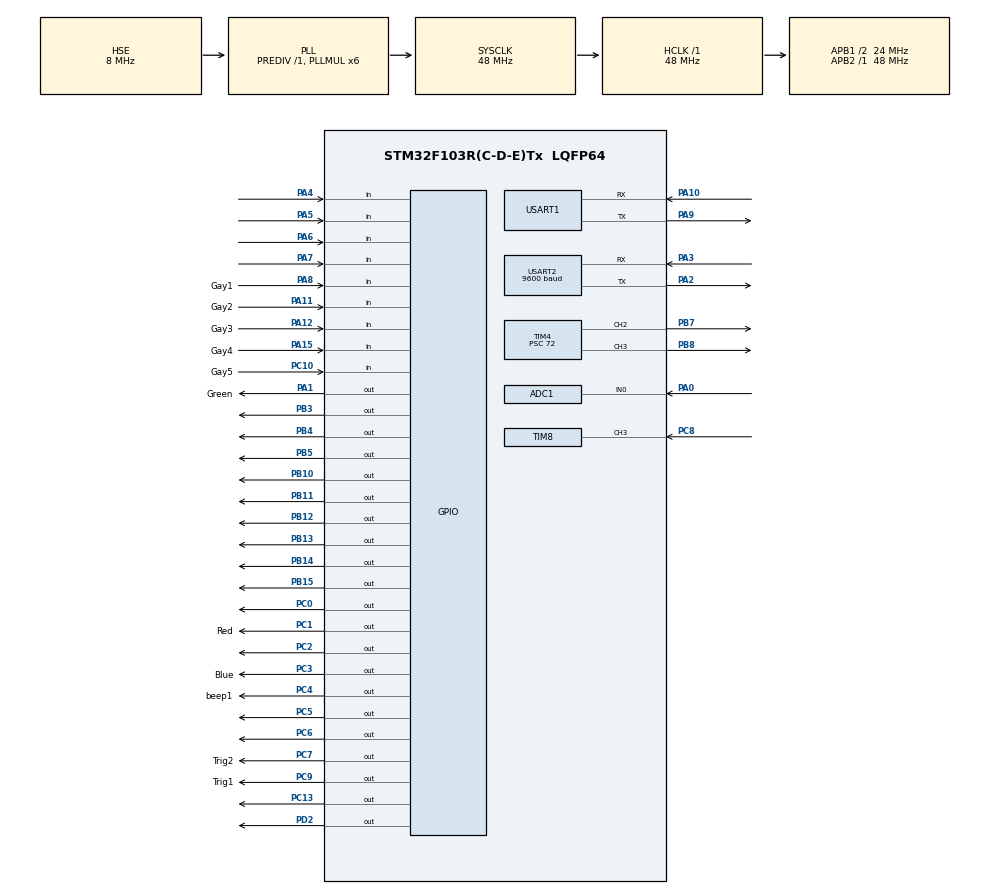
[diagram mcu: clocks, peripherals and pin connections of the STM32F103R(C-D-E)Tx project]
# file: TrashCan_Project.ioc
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ADC1.Channel-4\#ChannelRegularConversion=ADC_CHANNEL_0
ADC1.ContinuousConvMode=DISABLE
ADC1.EnableRegularConversion=ENABLE
ADC1.NbrOfConversion=1
ADC1.NbrOfConversionFlag=1
ADC1.Rank-4\#ChannelRegularConversion=1
ADC1.SamplingTime-4\#ChannelRegularConversion=ADC_SAMPLETIME_1CYCLE_5
ADC1.master=1
Dma.ADC1.0.Direction=DMA_PERIPH_TO_MEMORY
Dma.ADC1.0.Instance=DMA1_Channel1
Dma.ADC1.0.MemDataAlignment=DMA_MDATAALIGN_HALFWORD
Dma.ADC1.0.MemInc=DMA_MINC_ENABLE
Dma.ADC1.0.Mode=DMA_NORMAL
Dma.ADC1.0.PeriphDataAlignment=DMA_PDATAALIGN_HALFWORD
Dma.ADC1.0.PeriphInc=DMA_PINC_DISABLE
Dma.ADC1.0.Priority=DMA_PRIORITY_LOW
Dma.Request0=ADC1
Dma.Request1=USART2_RX
Dma.Request2=USART2_TX
Dma.USART2_RX.1.Direction=DMA_PERIPH_TO_MEMORY
Dma.USART2_RX.1.Instance=DMA1_Channel6
Dma.USART2_RX.1.MemDataAlignment=DMA_MDATAALIGN_BYTE
Dma.USART2_RX.1.MemInc=DMA_MINC_ENABLE
Dma.USART2_RX.1.Mode=DMA_NORMAL
Dma.USART2_RX.1.PeriphDataAlignment=DMA_PDATAALIGN_BYTE
Dma.USART2_RX.1.PeriphInc=DMA_PINC_DISABLE
Dma.USART2_RX.1.Priority=DMA_PRIORITY_LOW
Dma.USART2_TX.2.Direction=DMA_MEMORY_TO_PERIPH
Dma.USART2_TX.2.Instance=DMA1_Channel7
Dma.USART2_TX.2.MemDataAlignment=DMA_MDATAALIGN_BYTE
Dma.USART2_TX.2.MemInc=DMA_MINC_ENABLE
Dma.USART2_TX.2.Mode=DMA_NORMAL
Dma.USART2_TX.2.PeriphDataAlignment=DMA_PDATAALIGN_BYTE
Dma.USART2_TX.2.PeriphInc=DMA_PINC_DISABLE
Dma.USART2_TX.2.Priority=DMA_PRIORITY_LOW
Mcu.Family=STM32F1
Mcu.Name=STM32F103R(C-D-E)Tx
Mcu.Package=LQFP64
NVIC.DMA1_Channel1_IRQn=true\:0\:0\:false\:false\:true\:false\:true\:true
NVIC.DMA1_Channel6_IRQn=true\:0\:0\:false\:false\:true\:false\:true\:true
NVIC.DMA1_Channel7_IRQn=true\:0\:0\:false\:false\:true\:false\:true\:true
NVIC.PriorityGroup=NVIC_PRIORITYGROUP_4
NVIC.TIM6_IRQn=true\:0\:0\:false\:false\:true\:true\:true\:true
NVIC.TIM8_CC_IRQn=true\:0\:0\:false\:false\:true\:true\:true\:true
NVIC.USART2_IRQn=true\:0\:0\:false\:false\:true\:true\:true\:true
PA0-WKUP.Signal=ADCx_IN0
PA1.GPIO_Label=Green
PA1.Signal=GPIO_Output
PA10.Mode=Asynchronous
PA10.Signal=USART1_RX
PA11.GPIO_Label=Gay2
PA11.Signal=GPIO_Input
PA12.GPIO_Label=Gay3
PA12.Signal=GPIO_Input
PA13.Mode=Serial_Wire
PA13.Signal=SYS_JTMS-SWDIO
PA14.Mode=Serial_Wire
PA14.Signal=SYS_JTCK-SWCLK
PA15.GPIO_Label=Gay4
PA15.Signal=GPIO_Input
PA2.Mode=Asynchronous
PA2.Signal=USART2_TX
PA3.Mode=Asynchronous
PA3.Signal=USART2_RX
PA4.Signal=GPIO_Input
PA5.Signal=GPIO_Input
PA6.Signal=GPIO_Input
PA7.Signal=GPIO_Input
PA8.GPIO_Label=Gay1
PA8.Signal=GPIO_Input
PA9.Mode=Asynchronous
PA9.Signal=USART1_TX
PB10.GPIO_ModeDefaultOutputPP=GPIO_MODE_OUTPUT_OD
PB10.GPIO_PuPd=GPIO_PULLUP
PB10.GPIO_Speed=GPIO_SPEED_FREQ_HIGH
PB10.Signal=GPIO_Output
PB11.GPIO_ModeDefaultOutputPP=GPIO_MODE_OUTPUT_OD
PB11.GPIO_PuPd=GPIO_PULLUP
PB11.GPIO_Speed=GPIO_SPEED_FREQ_HIGH
PB11.Signal=GPIO_Output
PB12.GPIO_ModeDefaultOutputPP=GPIO_MODE_OUTPUT_OD
PB12.GPIO_PuPd=GPIO_NOPULL
PB12.GPIO_Speed=GPIO_SPEED_FREQ_HIGH
PB12.PinState=GPIO_PIN_RESET
PB12.Signal=GPIO_Output
PB13.GPIO_ModeDefaultOutputPP=GPIO_MODE_OUTPUT_PP
PB13.GPIO_PuPd=GPIO_NOPULL
PB13.GPIO_Speed=GPIO_SPEED_FREQ_MEDIUM
PB13.PinState=GPIO_PIN_SET
PB13.Signal=GPIO_Output
PB14.GPIO_ModeDefaultOutputPP=GPIO_MODE_OUTPUT_OD
PB14.GPIO_PuPd=GPIO_PULLUP
PB14.GPIO_Speed=GPIO_SPEED_FREQ_HIGH
PB14.PinState=GPIO_PIN_SET
PB14.Signal=GPIO_Output
PB15.GPIO_ModeDefaultOutputPP=GPIO_MODE_OUTPUT_OD
PB15.GPIO_PuPd=GPIO_PULLUP
PB15.GPIO_Speed=GPIO_SPEED_FREQ_HIGH
PB15.PinState=GPIO_PIN_RESET
PB15.Signal=GPIO_Output
PB3.Signal=GPIO_Output
PB4.Signal=GPIO_Output
PB5.Signal=GPIO_Output
PB7.Signal=S_TIM4_CH2
PB8.Signal=S_TIM4_CH3
PC0.GPIO_ModeDefaultOutputPP=GPIO_MODE_OUTPUT_OD
PC0.GPIO_PuPd=GPIO_PULLUP
PC0.GPIO_Speed=GPIO_SPEED_FREQ_HIGH
PC0.PinState=GPIO_PIN_RESET
PC0.Signal=GPIO_Output
PC1.GPIO_Label=Red
PC1.Signal=GPIO_Output
PC10.GPIO_Label=Gay5
PC10.Signal=GPIO_Input
PC13-TAMPER-RTC.GPIO_ModeDefaultOutputPP=GPIO_MODE_OUTPUT_OD
PC13-TAMPER-RTC.GPIO_PuPd=GPIO_PULLUP
PC13-TAMPER-RTC.GPIO_Speed=GPIO_SPEED_FREQ_HIGH
PC13-TAMPER-RTC.PinState=GPIO_PIN_RESET
PC13-TAMPER-RTC.Signal=GPIO_Output
PC2.Signal=GPIO_Output
PC3.GPIO_Label=Blue
PC3.Signal=GPIO_Output
PC4.GPIO_Label=beep1
PC4.GPIO_ModeDefaultOutputPP=GPIO_MODE_OUTPUT_PP
PC4.GPIO_PuPd=GPIO_PULLDOWN
PC4.PinState=GPIO_PIN_SET
PC4.Signal=GPIO_Output
PC5.GPIO_ModeDefaultOutputPP=GPIO_MODE_OUTPUT_OD
PC5.GPIO_PuPd=GPIO_PULLUP
PC5.GPIO_Speed=GPIO_SPEED_FREQ_HIGH
PC5.Signal=GPIO_Output
PC6.GPIO_ModeDefaultOutputPP=GPIO_MODE_OUTPUT_OD
PC6.GPIO_PuPd=GPIO_PULLUP
PC6.GPIO_Speed=GPIO_SPEED_FREQ_HIGH
PC6.Signal=GPIO_Output
PC7.GPIO_Label=Trig2
PC7.Signal=GPIO_Output
PC8.Signal=S_TIM8_CH3
PC9.GPIO_Label=Trig1
PC9.Signal=GPIO_Output
PD0-OSC_IN.Mode=HSE-External-Oscillator
PD0-OSC_IN.Signal=RCC_OSC_IN
PD1-OSC_OUT.Mode=HSE-External-Oscillator
PD1-OSC_OUT.Signal=RCC_OSC_OUT
PD2.Signal=GPIO_Output
ProjectManager.HeapSize=0x200
ProjectManager.StackSize=0x400
ProjectManager.TargetToolchain=STM32CubeIDE
RCC.ADCPresc=RCC_ADCPCLK2_DIV4
RCC.AHBFreq_Value=48000000
RCC.APB1CLKDivider=RCC_HCLK_DIV2
RCC.APB1Freq_Value=24000000
RCC.APB1TimFreq_Value=48000000
RCC.APB2Freq_Value=48000000
RCC.APB2TimFreq_Value=48000000
RCC.HCLKFreq_Value=48000000
RCC.PLLMUL=RCC_PLL_MUL6
RCC.PLLSourceVirtual=RCC_PLLSOURCE_HSE
RCC.SYSCLKFreq_VALUE=48000000
RCC.SYSCLKSource=RCC_SYSCLKSOURCE_PLLCLK
RCC.USBFreq_Value=48000000
SH.ADCx_IN0.0=ADC1_IN0,IN0
SH.S_TIM4_CH2.0=TIM4_CH2,PWM Generation2 CH2
SH.S_TIM4_CH3.0=TIM4_CH3,PWM Generation3 CH3
SH.S_TIM8_CH3.0=TIM8_CH3,Input_Capture3_from_TI3
TIM3.Period=2000-1
TIM3.Prescaler=720-1
TIM4.Channel-PWM\ Generation2\ CH2=TIM_CHANNEL_2
TIM4.Channel-PWM\ Generation3\ CH3=TIM_CHANNEL_3
TIM4.Period=999
TIM4.Prescaler=72
TIM6.Period=10000-1
TIM6.Prescaler=7200-1
TIM8.Channel-Input_Capture3_from_TI3=TIM_CHANNEL_3
TIM8.Channel-Input_Capture4_from_TI3_63=TIM_CHANNEL_4
TIM8.ICPolarity_CH4=TIM_INPUTCHANNELPOLARITY_FALLING
TIM8.Prescaler=72-1
USART1.VirtualMode=VM_ASYNC
USART2.BaudRate=9600
USART2.VirtualMode=VM_ASYNC
VP_TIM3_VS_ClockSourceINT.Mode=Internal
VP_TIM6_VS_ClockSourceINT.Mode=Enable_Timer
VP_TIM8_VS_ClockSourceINT.Mode=Internal
VP_TIM8_VS_indirect_ch3.Mode=Input_Capture4_from_TI3_63
board=custom

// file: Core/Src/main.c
/* USER CODE BEGIN Header */
/**
  ******************************************************************************
  * @file           : main.c
  * @brief          : Main program body
  ******************************************************************************
  * @attention
  *
  * Copyright (c) 2025 STMicroelectronics.
  * All rights reserved.
  *
  * This software is licensed under terms that can be found in the LICENSE file
  * in the root directory of this software component.
  * If no LICENSE file comes with this software, it is provided AS-IS.
  *
  ******************************************************************************
  */
/* USER CODE END Header */
#include "main.h"
#include "adc.h"
#include "dma.h"
#include "tim.h"
#include "usart.h"
#include "gpio.h"

/* USER CODE BEGIN Includes */
#include "User_Main.h"
#include "platform_log.h"

/* USER CODE END Includes */

void SystemClock_Config(void);

int main(void)
{

  /* MCU Configuration--------------------------------------------------------*/

  /* Reset of all peripherals, Initializes the Flash interface and the Systick. */
  HAL_Init();

  /* Configure the system clock */
  SystemClock_Config();

  /* Initialize all configured peripherals */
  MX_GPIO_Init();
  MX_DMA_Init();
  MX_TIM3_Init();
  MX_ADC1_Init();
  MX_USART2_UART_Init();
  MX_USART1_UART_Init();
  MX_TIM8_Init();
  MX_TIM4_Init();
  MX_TIM6_Init();
  /* USER CODE BEGIN 2 */
  PlatformLog_Init();
  User_Main();
  /* USER CODE END 2 */

  /* Infinite loop */
  while (1)
  {

  }
}

void SystemClock_Config(void)
{
  RCC_OscInitTypeDef RCC_OscInitStruct = {0};
  RCC_ClkInitTypeDef RCC_ClkInitStruct = {0};
  RCC_PeriphCLKInitTypeDef PeriphClkInit = {0};

  /** Initializes the RCC Oscillators according to the specified parameters
  * in the RCC_OscInitTypeDef structure.
  */
  RCC_OscInitStruct.OscillatorType = RCC_OSCILLATORTYPE_HSE;
  RCC_OscInitStruct.HSEState = RCC_HSE_ON;
  RCC_OscInitStruct.HSEPredivValue = RCC_HSE_PREDIV_DIV1;
  RCC_OscInitStruct.HSIState = RCC_HSI_ON;
  RCC_OscInitStruct.PLL.PLLState = RCC_PLL_ON;
  RCC_OscInitStruct.PLL.PLLSource = RCC_PLLSOURCE_HSE;
  RCC_OscInitStruct.PLL.PLLMUL = RCC_PLL_MUL6;
  if (HAL_RCC_OscConfig(&RCC_OscInitStruct) != HAL_OK)
  {
    Error_Handler();
  }

  /** Initializes the CPU, AHB and APB buses clocks
  */
  RCC_ClkInitStruct.ClockType = RCC_CLOCKTYPE_HCLK|RCC_CLOCKTYPE_SYSCLK
                              |RCC_CLOCKTYPE_PCLK1|RCC_CLOCKTYPE_PCLK2;
  RCC_ClkInitStruct.SYSCLKSource = RCC_SYSCLKSOURCE_PLLCLK;
  RCC_ClkInitStruct.AHBCLKDivider = RCC_SYSCLK_DIV1;
  RCC_ClkInitStruct.APB1CLKDivider = RCC_HCLK_DIV2;
  RCC_ClkInitStruct.APB2CLKDivider = RCC_HCLK_DIV1;

  if (HAL_RCC_ClockConfig(&RCC_ClkInitStruct, FLASH_LATENCY_1) != HAL_OK)
  {
    Error_Handler();
  }
  PeriphClkInit.PeriphClockSelection = RCC_PERIPHCLK_ADC;
  PeriphClkInit.AdcClockSelection = RCC_ADCPCLK2_DIV4;
  if (HAL_RCCEx_PeriphCLKConfig(&PeriphClkInit) != HAL_OK)
  {
    Error_Handler();
  }
}

void Error_Handler(void)
{
  __disable_irq();
  while (1)
  {
  }
}
